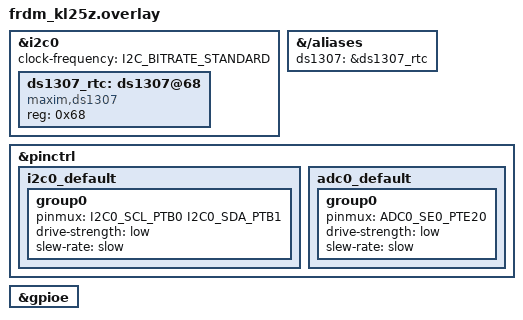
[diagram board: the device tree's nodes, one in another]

&i2c0 {
    status = "okay";
    clock-frequency = <I2C_BITRATE_STANDARD>;

    ds1307_rtc: ds1307@68 {
        compatible = "maxim,ds1307";
        reg = <0x68>;
        status = "okay";
    };
};

&{/aliases} {
    ds1307 = &ds1307_rtc;
};

&pinctrl {
    i2c0_default: i2c0_default {
        group0 {
            pinmux = <I2C0_SCL_PTB0 I2C0_SDA_PTB1>;
            drive-strength = "low";
            slew-rate = "slow";
        };
    };
    adc0_default: adc0_default {
            group0 {
                pinmux = <ADC0_SE0_PTE20>; 
                drive-strength = "low";
                slew-rate = "slow";
            };
        };

};

&gpioe {
    status = "okay";
};
